# DDR16SS0_CTLPHY_WRAP_CTL_CFG_CTLCFG register map
Vendor: Texas Instruments
Registers are 32-bit, read-write, reset 0x0 unless marked. A register's access mark holds for its fields unless they carry their own. Offsets are as the file gives them; [hi:lo] are bit positions; {n}, {i} and the like mark numbered series.

## DDR16SS0_CTLPHY_WRAP_CTL_CFG_CTLCFG (part 8 of 9)
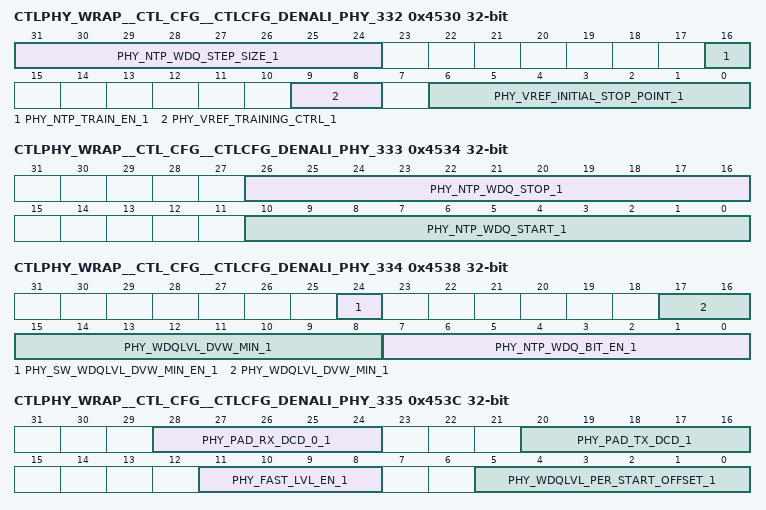
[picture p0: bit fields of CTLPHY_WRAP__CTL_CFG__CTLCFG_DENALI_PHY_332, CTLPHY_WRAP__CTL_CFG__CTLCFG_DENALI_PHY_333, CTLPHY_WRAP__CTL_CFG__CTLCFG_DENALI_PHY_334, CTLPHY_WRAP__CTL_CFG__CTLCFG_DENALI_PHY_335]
0x4530 CTLPHY_WRAP__CTL_CFG__CTLCFG_DENALI_PHY_332
  [31:24] PHY_NTP_WDQ_STEP_SIZE_1 — Step size of WR DQ slave delay during No-Topology training for slice 1.
  [16] PHY_NTP_TRAIN_EN_1 — Enable for No-Topology training for slice 1.
  [9:8] PHY_VREF_TRAINING_CTRL_1 — Data slice vref training enable control for slice 1.
  [6:0] PHY_VREF_INITIAL_STOP_POINT_1 — Data slice initial VREF training stop value for slice 1.
0x4534 CTLPHY_WRAP__CTL_CFG__CTLCFG_DENALI_PHY_333
  [26:16] PHY_NTP_WDQ_STOP_1 — End of WR DQ slave delay in No-Topology training for slice 1.
  [10:0] PHY_NTP_WDQ_START_1 — Starting WR DQ slave delay in No-Topology training for slice 1.
0x4538 CTLPHY_WRAP__CTL_CFG__CTLCFG_DENALI_PHY_334
  [24] PHY_SW_WDQLVL_DVW_MIN_EN_1 — SW override to enable use of PHY_WDQLVL_DVW_MIN for slice 1.
  [17:8] PHY_WDQLVL_DVW_MIN_1 — Minimum data valid window across DQs and ranks for slice 1.
  [7:0] PHY_NTP_WDQ_BIT_EN_1 — Enable Bit for WR DQ during No-Topology training for slice 1.
0x453C CTLPHY_WRAP__CTL_CFG__CTLCFG_DENALI_PHY_335
  [28:24] PHY_PAD_RX_DCD_0_1 — Controls RX_DCD pin for each pad for slice 1.
  [20:16] PHY_PAD_TX_DCD_1 — Controls TX_DCD pin for each pad for slice 1.
  [11:8] PHY_FAST_LVL_EN_1 — Enable for fast multi-pattern window search for slice 1.
  [5:0] PHY_WDQLVL_PER_START_OFFSET_1 — Peridic training start point offset for slice 1.
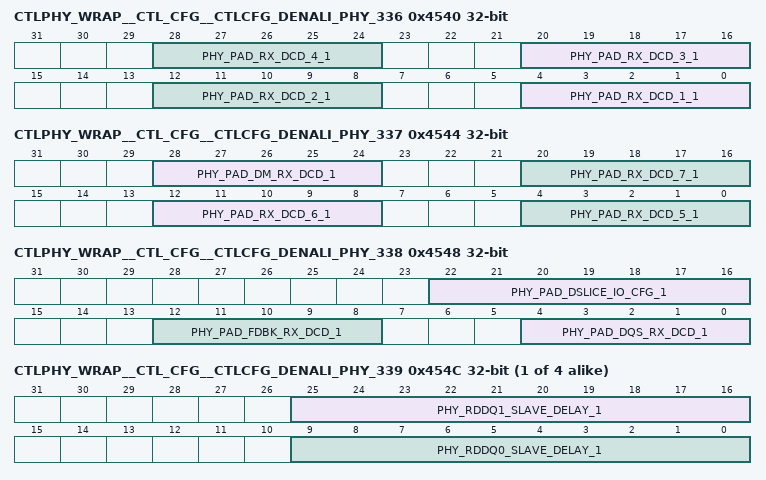
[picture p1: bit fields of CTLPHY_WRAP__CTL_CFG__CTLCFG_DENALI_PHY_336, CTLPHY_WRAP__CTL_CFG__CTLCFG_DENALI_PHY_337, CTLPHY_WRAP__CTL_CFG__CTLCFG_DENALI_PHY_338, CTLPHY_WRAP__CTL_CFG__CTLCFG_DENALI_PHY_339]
0x4540 CTLPHY_WRAP__CTL_CFG__CTLCFG_DENALI_PHY_336
  [8n-4:8n-8] PHY_PAD_RX_DCD_{n}_1 (n=1..4) — Controls RX_DCD pin for each pad for slice 1.
0x4544 CTLPHY_WRAP__CTL_CFG__CTLCFG_DENALI_PHY_337
  [28:24] PHY_PAD_DM_RX_DCD_1 — Controls RX_DCD pin for dm pad for slice 1.
  [20:16] PHY_PAD_RX_DCD_7_1 — Controls RX_DCD pin for each pad for slice 1.
  [12:8] PHY_PAD_RX_DCD_6_1 — Controls RX_DCD pin for each pad for slice 1.
  [4:0] PHY_PAD_RX_DCD_5_1 — Controls RX_DCD pin for each pad for slice 1.
0x4548 CTLPHY_WRAP__CTL_CFG__CTLCFG_DENALI_PHY_338
  [22:16] PHY_PAD_DSLICE_IO_CFG_1 — Controls PCLK/PARK pin for pad for slice 1.
  [12:8] PHY_PAD_FDBK_RX_DCD_1 — Controls RX_DCD pin for fdbk pad for slice 1.
  [4:0] PHY_PAD_DQS_RX_DCD_1 — Controls RX_DCD pin for dqs pad for slice 1.
{0x4000+4i} CTLPHY_WRAP__CTL_CFG__CTLCFG_DENALI_PHY_{i} (i=339..342)
  [25:16] PHY_RDDQ{2i-677}_SLAVE_DELAY_1 — Read DQ{2i-677} slave delay setting for slice 1.
  [9:0] PHY_RDDQ{2i-678}_SLAVE_DELAY_1 — Read DQ{2i-678} slave delay setting for slice 1.
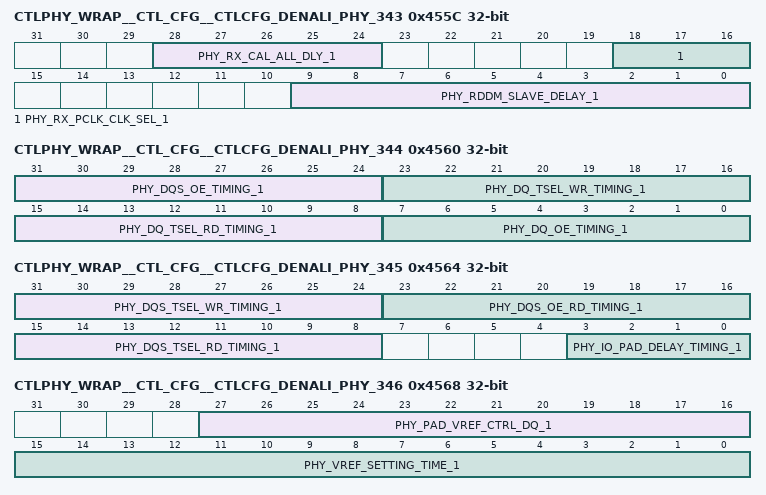
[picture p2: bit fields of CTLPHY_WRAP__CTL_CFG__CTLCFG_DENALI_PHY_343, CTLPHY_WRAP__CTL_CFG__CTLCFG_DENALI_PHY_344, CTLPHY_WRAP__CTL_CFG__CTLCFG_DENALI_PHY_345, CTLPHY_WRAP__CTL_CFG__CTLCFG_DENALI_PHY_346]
0x455C CTLPHY_WRAP__CTL_CFG__CTLCFG_DENALI_PHY_343
  [28:24] PHY_RX_CAL_ALL_DLY_1 — Defines the number of cycles/half cycles that the rx_cal_all_opad signal should be asserted for. There is a phy_rx_cal_all_dly_X parameter for each of the slices of data sent on the DFI data bus for slice 1.
  [18:16] PHY_RX_PCLK_CLK_SEL_1 — RX_PCLK clock frequency selection for slice 1.
  [9:0] PHY_RDDM_SLAVE_DELAY_1 — Read DM/DBI slave delay setting for slice 1. May be used for data swap.
0x4560 CTLPHY_WRAP__CTL_CFG__CTLCFG_DENALI_PHY_344
  [31:24] PHY_DQS_OE_TIMING_1 — Start/end timing values for DQS output enable signals for slice 1.
  [23:16] PHY_DQ_TSEL_WR_TIMING_1 — Start/end timing values for DQ/DM write based termination enable and select signals for slice 1.
  [15:8] PHY_DQ_TSEL_RD_TIMING_1 — Start/end timing values for DQ/DM read based termination enable and select signals for slice 1.
  [7:0] PHY_DQ_OE_TIMING_1 — Start/end timing values for DQ/DM output enable signals for slice 1.
0x4564 CTLPHY_WRAP__CTL_CFG__CTLCFG_DENALI_PHY_345
  [31:24] PHY_DQS_TSEL_WR_TIMING_1 — Start/end timing values for DQS write based termination enable and select signals for slice 1.
  [23:16] PHY_DQS_OE_RD_TIMING_1 — Start/end timing values for DQS read based OE extension for slice 1.
  [15:8] PHY_DQS_TSEL_RD_TIMING_1 — Start/end timing values for DQS read based termination enable and select signals for slice 1.
  [3:0] PHY_IO_PAD_DELAY_TIMING_1 — Feedback pad's OPAD and IPAD delay timing for slice 1.
0x4568 CTLPHY_WRAP__CTL_CFG__CTLCFG_DENALI_PHY_346
  [27:16] PHY_PAD_VREF_CTRL_DQ_1 — Pad VREF control settings for DQ slice 1.
  [15:0] PHY_VREF_SETTING_TIME_1 — Number of cycles for vref settle after setting is changed for slice 1.
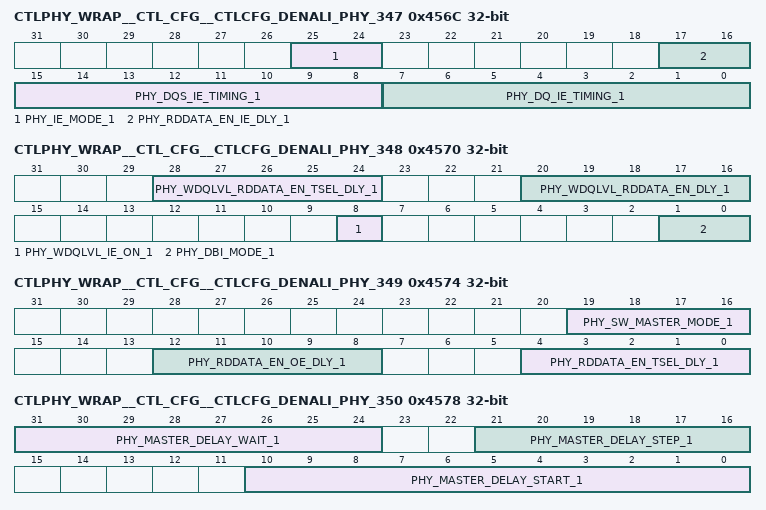
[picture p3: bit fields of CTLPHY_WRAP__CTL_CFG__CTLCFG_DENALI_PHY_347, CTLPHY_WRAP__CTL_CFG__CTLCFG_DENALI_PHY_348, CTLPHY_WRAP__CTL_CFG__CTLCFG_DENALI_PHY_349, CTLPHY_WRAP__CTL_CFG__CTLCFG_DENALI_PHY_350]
0x456C CTLPHY_WRAP__CTL_CFG__CTLCFG_DENALI_PHY_347
  [25:24] PHY_IE_MODE_1 — Input enable mode bits for slice 1. Bit [0] enables the mode where the input enables are always on; set to 1 to enable. Bit [1] disables the input enable on the DM signal; set to 1 to disable.
  [17:16] PHY_RDDATA_EN_IE_DLY_1 — Number of cycles that the dfi_rddata_en signal is earlier than necessary for input enable generation for slice 1.
  [15:8] PHY_DQS_IE_TIMING_1 — Start/end timing values for DQS input enable signals for slice 1.
  [7:0] PHY_DQ_IE_TIMING_1 — Start/end timing values for DQ/DM input enable signals for slice 1.
0x4570 CTLPHY_WRAP__CTL_CFG__CTLCFG_DENALI_PHY_348
  [28:24] PHY_WDQLVL_RDDATA_EN_TSEL_DLY_1 — For WR DQ training, the number of cycles that the dfi_rddata_en signal is earlier than necessary for TSEL enable generation for slice 1.
  [20:16] PHY_WDQLVL_RDDATA_EN_DLY_1 — For WR DQ training, the number of cycles that the dfi_rddata_en signal is early for slice 1.
  [8] PHY_WDQLVL_IE_ON_1 — IE control, 1 meams IE is always on during WR DQ training for slice 1.
  [1:0] PHY_DBI_MODE_1 — DBI mode for slice 1. Bit [0] enables return of DBI read data.
0x4574 CTLPHY_WRAP__CTL_CFG__CTLCFG_DENALI_PHY_349
  [19:16] PHY_SW_MASTER_MODE_1 — Master delay line override settings for slice 1. Bit [0] enables software half clock mode. Bit [1] is the software half clock mode value. Bit [2] enables software bypass mode. Bit [3] is the software bypass mode value.
  [12:8] PHY_RDDATA_EN_OE_DLY_1 — Number of cycles that the dfi_rddata_en signal is earlier than necessary for LP4 OE extension generation for slice 1.
  [4:0] PHY_RDDATA_EN_TSEL_DLY_1 — Number of cycles that the dfi_rddata_en signal is earlier than necessary for TSEL enable generation for slice 1.
0x4578 CTLPHY_WRAP__CTL_CFG__CTLCFG_DENALI_PHY_350
  [31:24] PHY_MASTER_DELAY_WAIT_1 — Wait cycles for master delay line locking algorithm for slice 1. Bits [3:0] are the cycle wait count after a calibration clock setting change. Bits [7:4] are the cycle wait count after a master delay setting change.
  [21:16] PHY_MASTER_DELAY_STEP_1 — Incremental step size for master delay line locking algorithm for slice 1.
  [10:0] PHY_MASTER_DELAY_START_1 — Start value for master delay line locking algorithm for slice 1.
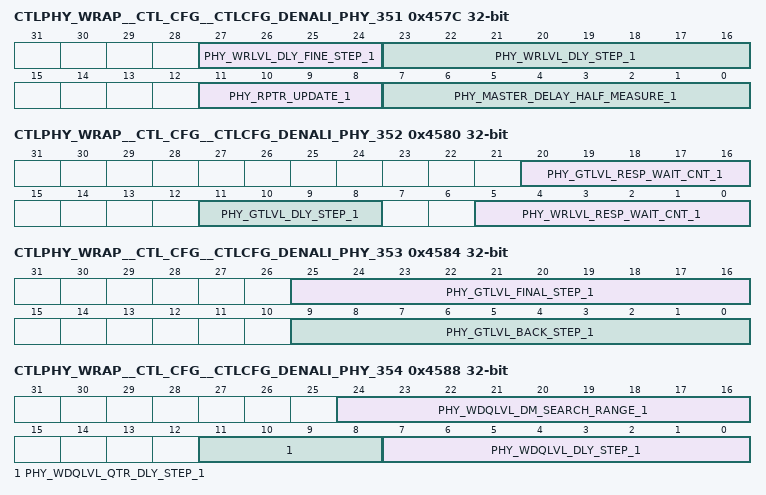
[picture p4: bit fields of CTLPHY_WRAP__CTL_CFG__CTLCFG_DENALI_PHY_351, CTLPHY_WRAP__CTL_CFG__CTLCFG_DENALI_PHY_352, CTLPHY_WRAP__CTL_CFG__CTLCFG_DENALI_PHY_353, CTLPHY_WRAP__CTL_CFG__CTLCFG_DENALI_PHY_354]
0x457C CTLPHY_WRAP__CTL_CFG__CTLCFG_DENALI_PHY_351
  [27:24] PHY_WRLVL_DLY_FINE_STEP_1 — DQS slave delay fine step size during write leveling for slice 1.
  [23:16] PHY_WRLVL_DLY_STEP_1 — DQS slave delay step size during write leveling for slice 1.
  [11:8] PHY_RPTR_UPDATE_1 — Offset in cycles from the dfi_rddata_en signal to release data from the entry FIFO for slice 1.
  [7:0] PHY_MASTER_DELAY_HALF_MEASURE_1 — Defines the number of delay line elements to be considered in determing whether to lock to a half clock cycle in the data slice master for slice 1.
0x4580 CTLPHY_WRAP__CTL_CFG__CTLCFG_DENALI_PHY_352
  [20:16] PHY_GTLVL_RESP_WAIT_CNT_1 — Number of cycles + 4 to wait between dfi_rddata_en and the sampling of the DQS during gate training for slice 1. The valid range is 0x0 to 0xB.
  [11:8] PHY_GTLVL_DLY_STEP_1 — DQS slave delay step size during gate training for slice 1.
  [5:0] PHY_WRLVL_RESP_WAIT_CNT_1 — Number of cycles to wait between dfi_wrlvl_strobe and the sampling of the DQs during write leveling for slice 1.
0x4584 CTLPHY_WRAP__CTL_CFG__CTLCFG_DENALI_PHY_353
  [25:16] PHY_GTLVL_FINAL_STEP_1 — Final backup step delay used in gate training algorithm for slice 1.
  [9:0] PHY_GTLVL_BACK_STEP_1 — Interim backup step delay used in gate training algorithm for slice 1.
0x4588 CTLPHY_WRAP__CTL_CFG__CTLCFG_DENALI_PHY_354
  [24:16] PHY_WDQLVL_DM_SEARCH_RANGE_1 — The dm slave delay search range for non-lpddr4 DM training for slice 1.
  [11:8] PHY_WDQLVL_QTR_DLY_STEP_1 — Defines the step granularity for the logic to use once an edge is found for slice 1. When this occurs, the logic jumps back to the previous invalid value and uses this step size to determine a more accurate delay value.
  [7:0] PHY_WDQLVL_DLY_STEP_1 — DQ slave delay step size during write data leveling for slice 1.
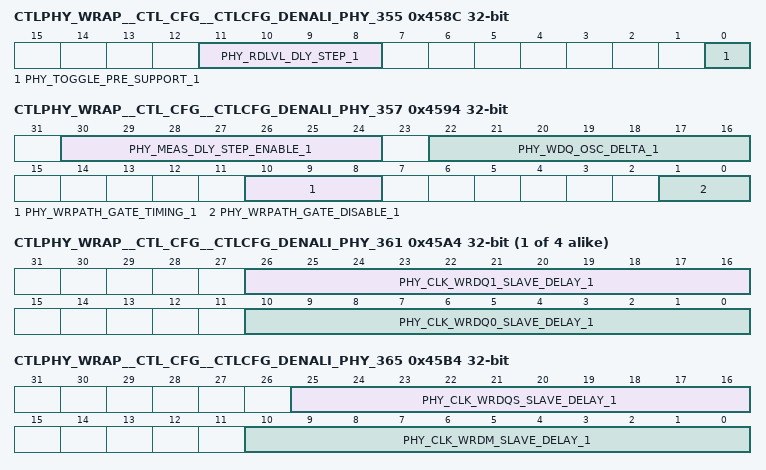
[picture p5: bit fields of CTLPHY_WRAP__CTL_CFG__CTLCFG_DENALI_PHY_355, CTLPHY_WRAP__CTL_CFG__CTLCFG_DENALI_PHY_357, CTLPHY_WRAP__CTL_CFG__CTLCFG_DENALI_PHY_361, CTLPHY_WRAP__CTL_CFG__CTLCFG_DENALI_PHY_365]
0x458C CTLPHY_WRAP__CTL_CFG__CTLCFG_DENALI_PHY_355
  [11:8] PHY_RDLVL_DLY_STEP_1 — DQS slave delay step size during read leveling for slice 1.
  [0] PHY_TOGGLE_PRE_SUPPORT_1 — Support the toggle read preamble for LPDDR4 for slice 1.
0x4590 CTLPHY_WRAP__CTL_CFG__CTLCFG_DENALI_PHY_356
  [9:0] PHY_RDLVL_MAX_EDGE_1 — The maximun rdlvl slave delay search window for read eye training for slice 1.
0x4594 CTLPHY_WRAP__CTL_CFG__CTLCFG_DENALI_PHY_357
  [30:24] PHY_MEAS_DLY_STEP_ENABLE_1 — Data slice training step definition using phy_meas_dly_step_value for slice 1.
  [22:16] PHY_WDQ_OSC_DELTA_1 — Slave delay offset that applies to a 1 bit change of dfi_wdq_osc_code for slice 1.
  [10:8] PHY_WRPATH_GATE_TIMING_1 — Write path clock gating timing for slice 1. it means additional clock number to write path clock gate
  [1:0] PHY_WRPATH_GATE_DISABLE_1 — Write path clock gating disable for slice 1. [0]: disable pull in wrdata_en; [1]: disable write path clock gating, clock always on
0x4598 CTLPHY_WRAP__CTL_CFG__CTLCFG_DENALI_PHY_358
  [4:0] PHY_RDDATA_EN_DLY_1 — Number of cycles that the dfi_rddata_en signal is early for slice 1.
0x459C CTLPHY_WRAP__CTL_CFG__CTLCFG_DENALI_PHY_359
  [31:0] PHY_DQ_DM_SWIZZLE0_1 — DQ/DM bit swizzling 0 for slice 1. Bits [3:0] inform the PHY which bit in {DM,DQ]} map to DQ0, Bits [7:4] inform the PHY which bit in {DM,DQ} map to DQ1, etc.
0x45A0 CTLPHY_WRAP__CTL_CFG__CTLCFG_DENALI_PHY_360
  [3:0] PHY_DQ_DM_SWIZZLE1_1 — DQ/DM bit swizzling 1 for slice 1. Bits [3:0] inform the PHY which bit in {DM,DQ]} map to DM.
{0x4000+4i} CTLPHY_WRAP__CTL_CFG__CTLCFG_DENALI_PHY_{i} (i=361..364)
  [26:16] PHY_CLK_WRDQ{2i-721}_SLAVE_DELAY_1 — Write clock slave delay setting for DQ{2i-721} for slice 1.
  [10:0] PHY_CLK_WRDQ{2i-722}_SLAVE_DELAY_1 — Write clock slave delay setting for DQ{2i-722} for slice 1.
0x45B4 CTLPHY_WRAP__CTL_CFG__CTLCFG_DENALI_PHY_365
  [25:16] PHY_CLK_WRDQS_SLAVE_DELAY_1 — Write clock slave delay setting for DQS for slice 1.
  [10:0] PHY_CLK_WRDM_SLAVE_DELAY_1 — Write clock slave delay setting for DM for slice 1.
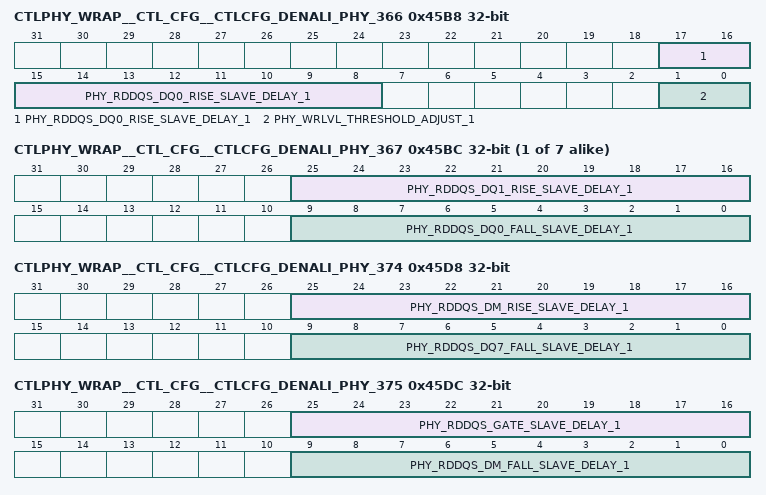
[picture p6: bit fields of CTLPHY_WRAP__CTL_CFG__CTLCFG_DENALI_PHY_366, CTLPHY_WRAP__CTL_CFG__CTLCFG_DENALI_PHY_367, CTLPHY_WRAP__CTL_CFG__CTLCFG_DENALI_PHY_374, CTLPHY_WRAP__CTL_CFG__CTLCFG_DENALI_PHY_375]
0x45B8 CTLPHY_WRAP__CTL_CFG__CTLCFG_DENALI_PHY_366
  [17:8] PHY_RDDQS_DQ0_RISE_SLAVE_DELAY_1 — Rising edge read DQS slave delay setting for DQ0 for slice 1.
  [1:0] PHY_WRLVL_THRESHOLD_ADJUST_1 — Write level threshold adjust value based on those thresholds for DQS for slice 1.
{0x4000+4i} CTLPHY_WRAP__CTL_CFG__CTLCFG_DENALI_PHY_{i} (i=367..373)
  [25:16] PHY_RDDQS_DQ{i-366}_RISE_SLAVE_DELAY_1 — Rising edge read DQS slave delay setting for DQ{i-366} for slice 1.
  [9:0] PHY_RDDQS_DQ{i-367}_FALL_SLAVE_DELAY_1 — Falling edge read DQS slave delay setting for DQ{i-367} for slice 1.
0x45D8 CTLPHY_WRAP__CTL_CFG__CTLCFG_DENALI_PHY_374
  [25:16] PHY_RDDQS_DM_RISE_SLAVE_DELAY_1 — Rising edge read DQS slave delay setting for DM for slice 1.
  [9:0] PHY_RDDQS_DQ7_FALL_SLAVE_DELAY_1 — Falling edge read DQS slave delay setting for DQ7 for slice 1.
0x45DC CTLPHY_WRAP__CTL_CFG__CTLCFG_DENALI_PHY_375
  [25:16] PHY_RDDQS_GATE_SLAVE_DELAY_1 — Read DQS slave delay setting for slice 1.
  [9:0] PHY_RDDQS_DM_FALL_SLAVE_DELAY_1 — Falling edge read DQS slave delay setting for DM for slice 1.
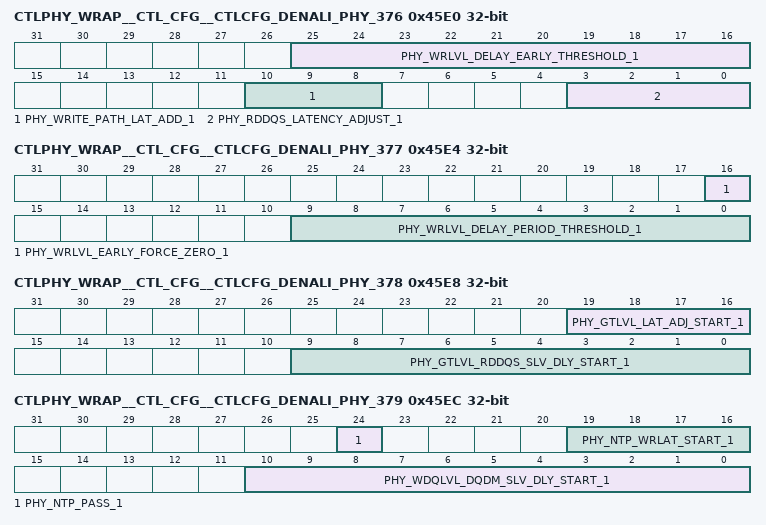
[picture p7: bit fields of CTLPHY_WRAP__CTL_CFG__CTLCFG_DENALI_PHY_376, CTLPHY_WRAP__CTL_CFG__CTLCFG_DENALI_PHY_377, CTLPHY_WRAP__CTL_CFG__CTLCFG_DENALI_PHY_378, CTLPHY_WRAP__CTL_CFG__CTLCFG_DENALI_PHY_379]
0x45E0 CTLPHY_WRAP__CTL_CFG__CTLCFG_DENALI_PHY_376
  [25:16] PHY_WRLVL_DELAY_EARLY_THRESHOLD_1 — Write level delay threshold above which will be considered in previous cycle for slice 1.
  [10:8] PHY_WRITE_PATH_LAT_ADD_1 — Number of cycles to delay the incoming dfi_wrdata_en/dfi_wrdata signals for slice 1.
  [3:0] PHY_RDDQS_LATENCY_ADJUST_1 — Number of cycles to delay the incoming dfi_rddata_en for read DQS gate generation for slice 1.
0x45E4 CTLPHY_WRAP__CTL_CFG__CTLCFG_DENALI_PHY_377
  [16] PHY_WRLVL_EARLY_FORCE_ZERO_1 — Force the final write level delay value [that meets the early threshold] to 0 for slice 1.
  [9:0] PHY_WRLVL_DELAY_PERIOD_THRESHOLD_1 — Write level delay threshold below which will add a cycle of write path latency for slice 1.
0x45E8 CTLPHY_WRAP__CTL_CFG__CTLCFG_DENALI_PHY_378
  [19:16] PHY_GTLVL_LAT_ADJ_START_1 — Initial read DQS gate cycle delay from dfi_rddata_en during gate training for slice 1.
  [9:0] PHY_GTLVL_RDDQS_SLV_DLY_START_1 — Initial read DQS gate slave delay setting during gate training for slice 1.
0x45EC CTLPHY_WRAP__CTL_CFG__CTLCFG_DENALI_PHY_379
  [24] PHY_NTP_PASS_1 — Indicates if No-topology training found a passing result for slice 1.
  [19:16] PHY_NTP_WRLAT_START_1 — Initial value for phy_write_path_lat_add for No-topology training and early threshold for slice 1.
  [10:0] PHY_WDQLVL_DQDM_SLV_DLY_START_1 — Initial DQ/DM slave delay setting during write data leveling for slice 1.
0x45F0 CTLPHY_WRAP__CTL_CFG__CTLCFG_DENALI_PHY_380
  [9:0] PHY_RDLVL_RDDQS_DQ_SLV_DLY_START_1 — Read leveling starting value for the DQS/DQ slave delay settings for slice 1.
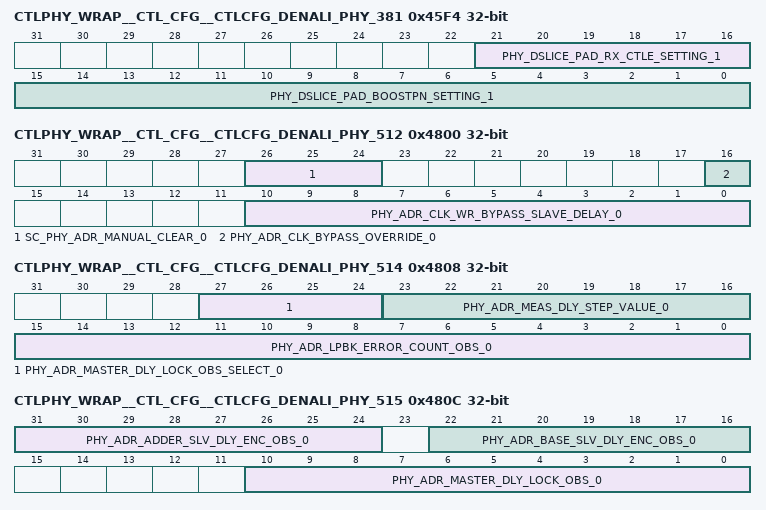
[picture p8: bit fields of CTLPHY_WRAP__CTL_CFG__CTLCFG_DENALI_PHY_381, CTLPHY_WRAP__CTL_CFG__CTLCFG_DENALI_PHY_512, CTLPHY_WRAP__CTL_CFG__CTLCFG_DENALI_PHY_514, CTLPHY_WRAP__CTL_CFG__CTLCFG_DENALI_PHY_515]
0x45F4 CTLPHY_WRAP__CTL_CFG__CTLCFG_DENALI_PHY_381
  [21:16] PHY_DSLICE_PAD_RX_CTLE_SETTING_1 — Setting for RX ctle P/N of pad for slice 1.
  [15:0] PHY_DSLICE_PAD_BOOSTPN_SETTING_1 — Setting for boost P/N of pad for slice 1.
0x4800 CTLPHY_WRAP__CTL_CFG__CTLCFG_DENALI_PHY_512 access per field
  [26:24] SC_PHY_ADR_MANUAL_CLEAR_0 wo — Manual reset/clear of internal logic for address slice 0. Bit [0] is reset of master delay min/max lock values. Bit [1] is manual reset of master delay unlock counter. Bit [2] clears the loopback error/results registers. Set each bit to 1 to reset. WRITE-ONLY
  [16] PHY_ADR_CLK_BYPASS_OVERRIDE_0 rw — Bypass mode override setting for address slice 0. Set to 1 to enable.
  [10:0] PHY_ADR_CLK_WR_BYPASS_SLAVE_DELAY_0 rw — Command/Address clock bypass mode slave delay setting for address slice 0.
0x4804 CTLPHY_WRAP__CTL_CFG__CTLCFG_DENALI_PHY_513 ro reset 0x1000
  [31:0] PHY_ADR_LPBK_RESULT_OBS_0 — Observation register containing loopback status/results for address slice 0. READ-ONLY
0x4808 CTLPHY_WRAP__CTL_CFG__CTLCFG_DENALI_PHY_514 access per field
  [27:24] PHY_ADR_MASTER_DLY_LOCK_OBS_SELECT_0 rw — Select value to map the internal master delay observation registers to the accessible master delay observation register for address slice 0.
  [23:16] PHY_ADR_MEAS_DLY_STEP_VALUE_0 ro — Contains the fraction of a cycle in 1 delay element numerator with demominator of 512, for address slice 0. READ-ONLY
  [15:0] PHY_ADR_LPBK_ERROR_COUNT_OBS_0 ro — Observation register containing total number of loopback error data for address slice 0. READ-ONLY
0x480C CTLPHY_WRAP__CTL_CFG__CTLCFG_DENALI_PHY_515 ro
  [31:24] PHY_ADR_ADDER_SLV_DLY_ENC_OBS_0 — Observation register containing addr slave delay for address slice 0. READ-ONLY
  [22:16] PHY_ADR_BASE_SLV_DLY_ENC_OBS_0 — Observation register containing base slave delay for address slice 0. READ-ONLY
  [10:0] PHY_ADR_MASTER_DLY_LOCK_OBS_0 — Observation register containing master delay results for address slice 0. READ-ONLY
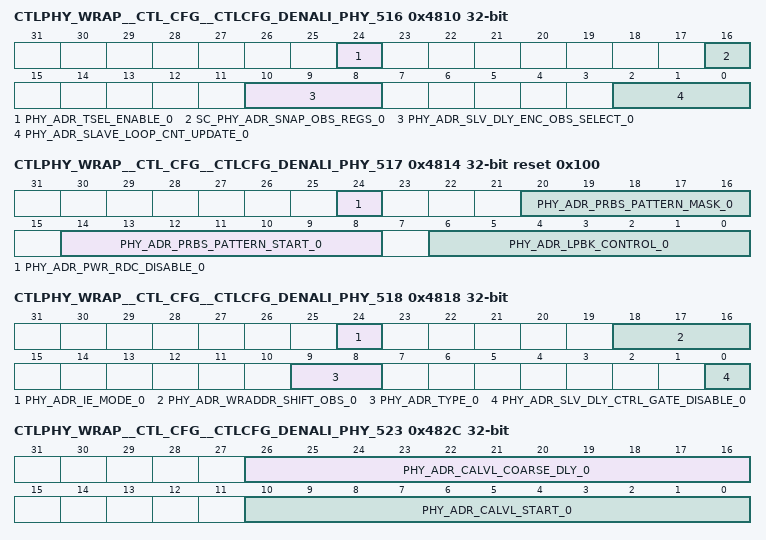
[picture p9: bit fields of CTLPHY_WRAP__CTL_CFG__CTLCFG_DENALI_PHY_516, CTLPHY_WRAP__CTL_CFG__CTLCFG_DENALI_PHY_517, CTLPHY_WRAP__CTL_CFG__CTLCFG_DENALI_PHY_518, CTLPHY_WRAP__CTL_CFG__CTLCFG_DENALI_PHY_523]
0x4810 CTLPHY_WRAP__CTL_CFG__CTLCFG_DENALI_PHY_516 access per field
  [24] PHY_ADR_TSEL_ENABLE_0 rw — Enables tsel_en for address slice 0.
  [16] SC_PHY_ADR_SNAP_OBS_REGS_0 wo — Initiates a snapshot of the internal observation registers for address slice 0. Set to 1 to trigger. WRITE-ONLY
  [10:8] PHY_ADR_SLV_DLY_ENC_OBS_SELECT_0 rw — Select value to map the addr bits delay observation registers to the accessible delay observation register for address slice 0.
  [2:0] PHY_ADR_SLAVE_LOOP_CNT_UPDATE_0 rw — Reserved for address slice 0.
0x4814 CTLPHY_WRAP__CTL_CFG__CTLCFG_DENALI_PHY_517 reset 0x100
  [24] PHY_ADR_PWR_RDC_DISABLE_0 — Power reduction disable for address slice 0.
  [20:16] PHY_ADR_PRBS_PATTERN_MASK_0 — PRBS7 mask signal for address slice 0.
  [14:8] PHY_ADR_PRBS_PATTERN_START_0 — PRBS7 start pattern for address slice 0.
  [6:0] PHY_ADR_LPBK_CONTROL_0 — Loopback control bits for address slice 0.
0x4818 CTLPHY_WRAP__CTL_CFG__CTLCFG_DENALI_PHY_518 access per field
  [24] PHY_ADR_IE_MODE_0 rw — Input enable control for address slice 0.
  [18:16] PHY_ADR_WRADDR_SHIFT_OBS_0 ro — Observation register containing automatic half cycle and cycle shift values for address slice 0. READ-ONLY
  [9:8] PHY_ADR_TYPE_0 rw — DRAM type for address slice 0.
  [0] PHY_ADR_SLV_DLY_CTRL_GATE_DISABLE_0 rw — Power reduction slv_dly_control block gate disable for address slice 0.
0x481C CTLPHY_WRAP__CTL_CFG__CTLCFG_DENALI_PHY_519
  [26:0] PHY_ADR_DDL_MODE_0 — DDL mode for address slice 0.
0x4820 CTLPHY_WRAP__CTL_CFG__CTLCFG_DENALI_PHY_520
  [5:0] PHY_ADR_DDL_MASK_0 — DDL mask for address slice 0.
0x4824 CTLPHY_WRAP__CTL_CFG__CTLCFG_DENALI_PHY_521 ro
  [31:0] PHY_ADR_DDL_TEST_OBS_0 — Observation register containing DDL test bits for address slice 0. READ-ONLY
0x4828 CTLPHY_WRAP__CTL_CFG__CTLCFG_DENALI_PHY_522 ro
  [31:0] PHY_ADR_DDL_TEST_MSTR_DLY_OBS_0 — Observation register containing master DDL bits for address slice 0. READ-ONLY
0x482C CTLPHY_WRAP__CTL_CFG__CTLCFG_DENALI_PHY_523
  [26:16] PHY_ADR_CALVL_COARSE_DLY_0 — Coarse CA training DDL increment value for address slice 0.
  [10:0] PHY_ADR_CALVL_START_0 — CA training DDL start value for address slice 0.
0x4830 CTLPHY_WRAP__CTL_CFG__CTLCFG_DENALI_PHY_524
  [10:0] PHY_ADR_CALVL_QTR_0 — CA training DDL quarter cycle delay value for address slice 0.
0x4834 CTLPHY_WRAP__CTL_CFG__CTLCFG_DENALI_PHY_525
  [23:0] PHY_ADR_CALVL_SWIZZLE0_0 — CA training RD DQ bit swizzle map 0 for address slice 0.
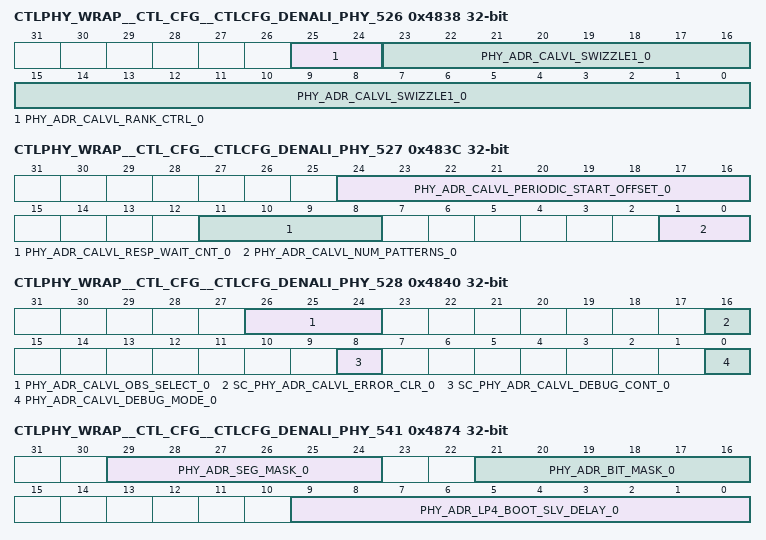
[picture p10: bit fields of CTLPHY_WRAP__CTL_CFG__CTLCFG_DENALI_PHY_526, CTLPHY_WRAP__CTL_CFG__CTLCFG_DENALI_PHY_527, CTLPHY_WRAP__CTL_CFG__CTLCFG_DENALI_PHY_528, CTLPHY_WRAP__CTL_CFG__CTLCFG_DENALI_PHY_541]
0x4838 CTLPHY_WRAP__CTL_CFG__CTLCFG_DENALI_PHY_526
  [25:24] PHY_ADR_CALVL_RANK_CTRL_0 — CA training rank aggregation control bits for address slice 0.
  [23:0] PHY_ADR_CALVL_SWIZZLE1_0 — CA training RD DQ bit swizzle map 1 for address slice 0.
0x483C CTLPHY_WRAP__CTL_CFG__CTLCFG_DENALI_PHY_527
  [24:16] PHY_ADR_CALVL_PERIODIC_START_OFFSET_0 — Relative offset to start periodic CALVL from previous result
  [11:8] PHY_ADR_CALVL_RESP_WAIT_CNT_0 — Number of samples to wait before sampling response during CA training for address slice 0.
  [1:0] PHY_ADR_CALVL_NUM_PATTERNS_0 — Number of patterns to use during CA training for address slice 0.
0x4840 CTLPHY_WRAP__CTL_CFG__CTLCFG_DENALI_PHY_528 access per field
  [26:24] PHY_ADR_CALVL_OBS_SELECT_0 rw — CA bit lane to observe result from OBS0 during CA training for address slice 0.
  [16] SC_PHY_ADR_CALVL_ERROR_CLR_0 wo — Clears the CA training state machine error status for address slice 0. Set to 1 to trigger. WRITE-ONLY
  [8] SC_PHY_ADR_CALVL_DEBUG_CONT_0 wo — Allows the CA training state machine to advance [when in debug mode] for address slice 0. Set to 1 to trigger. WRITE-ONLY
  [0] PHY_ADR_CALVL_DEBUG_MODE_0 rw — Enables CA training debug mode for address slice 0. Set to 1 to enable.
0x4844 CTLPHY_WRAP__CTL_CFG__CTLCFG_DENALI_PHY_529 ro
  [31:0] PHY_ADR_CALVL_OBS0_0 — Observation register contains lane specific CA training bits for slice 0. READ-ONLY
0x4848 CTLPHY_WRAP__CTL_CFG__CTLCFG_DENALI_PHY_530 ro
  [31:0] PHY_ADR_CALVL_OBS1_0 — Observation register contains general CA training bits for slice 0. READ-ONLY
0x484C CTLPHY_WRAP__CTL_CFG__CTLCFG_DENALI_PHY_531 ro reset 0x100
  [31:0] PHY_ADR_CALVL_OBS2_0 — Observation register contains periodic CA training bits for slice 0. READ-ONLY
0x4850 CTLPHY_WRAP__CTL_CFG__CTLCFG_DENALI_PHY_532
  [19:0] PHY_ADR_CALVL_FG_0_0 — CA training foreground pattern 0 for address slice 0.
0x4854 CTLPHY_WRAP__CTL_CFG__CTLCFG_DENALI_PHY_533
  [19:0] PHY_ADR_CALVL_BG_0_0 — CA training background pattern 0 for address slice 0.
0x4858 CTLPHY_WRAP__CTL_CFG__CTLCFG_DENALI_PHY_534
  [19:0] PHY_ADR_CALVL_FG_1_0 — CA training foreground pattern 1 for address slice 0.
0x485C CTLPHY_WRAP__CTL_CFG__CTLCFG_DENALI_PHY_535
  [19:0] PHY_ADR_CALVL_BG_1_0 — CA training background pattern 1 for address slice 0.
0x4860 CTLPHY_WRAP__CTL_CFG__CTLCFG_DENALI_PHY_536
  [19:0] PHY_ADR_CALVL_FG_2_0 — CA training foreground pattern 2 for address slice 0.
0x4864 CTLPHY_WRAP__CTL_CFG__CTLCFG_DENALI_PHY_537
  [19:0] PHY_ADR_CALVL_BG_2_0 — CA training background pattern 2 for address slice 0.
0x4868 CTLPHY_WRAP__CTL_CFG__CTLCFG_DENALI_PHY_538
  [19:0] PHY_ADR_CALVL_FG_3_0 — CA training foreground pattern 3 for address slice 0.
0x486C CTLPHY_WRAP__CTL_CFG__CTLCFG_DENALI_PHY_539
  [19:0] PHY_ADR_CALVL_BG_3_0 — CA training background pattern 3 for address slice 0.
0x4870 CTLPHY_WRAP__CTL_CFG__CTLCFG_DENALI_PHY_540
  [29:0] PHY_ADR_ADDR_SEL_0 — Selects which DFI address pins connect to which CA pins for LPDDR3/4 for address slice 0.
0x4874 CTLPHY_WRAP__CTL_CFG__CTLCFG_DENALI_PHY_541
  [29:24] PHY_ADR_SEG_MASK_0 — Segment mask bit for address slice 0. Set to 1 to indicate that the bit is either CA 4 or CA 9.
  [21:16] PHY_ADR_BIT_MASK_0 — Mask bit for address slice 0. Set to 1 to indicate that the bit is used.
  [9:0] PHY_ADR_LP4_BOOT_SLV_DELAY_0 — Address slave delay setting during the LPDDR4 boot frequency operation for address slice 0.
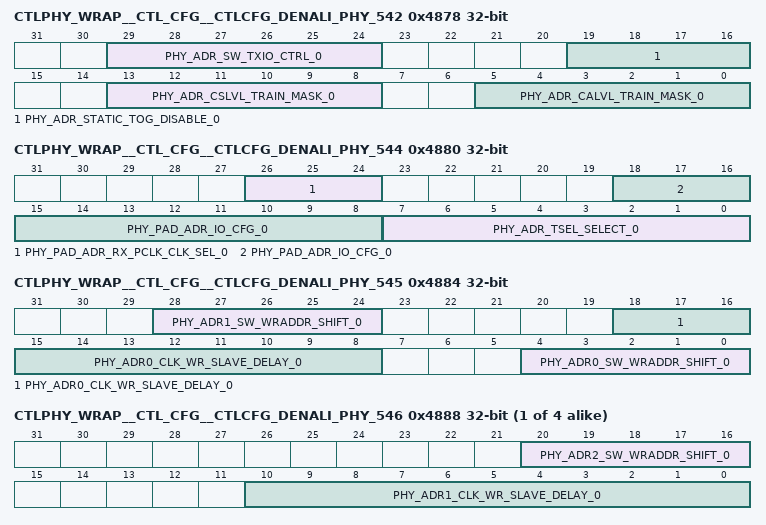
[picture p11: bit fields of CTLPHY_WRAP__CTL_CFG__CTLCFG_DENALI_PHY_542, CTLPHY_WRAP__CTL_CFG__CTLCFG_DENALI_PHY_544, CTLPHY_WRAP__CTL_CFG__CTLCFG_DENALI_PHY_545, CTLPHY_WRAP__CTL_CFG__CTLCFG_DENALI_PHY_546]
0x4878 CTLPHY_WRAP__CTL_CFG__CTLCFG_DENALI_PHY_542
  [29:24] PHY_ADR_SW_TXIO_CTRL_0 — Controls address pad output enable for address slice 0. Set to 1 to disable output enable.
  [19:16] PHY_ADR_STATIC_TOG_DISABLE_0 — Toggle control during static activity for address slice 0. Set bit to dsiable toggling, bit0: Write path delay line, bit1: Read path delay line, bit2: Read data path, bit3: clk_phy, bit4: master delay line.
  [13:8] PHY_ADR_CSLVL_TRAIN_MASK_0 — Mask bit for CS training participation for address slice 0. Set to 1 to indicate that the bit is participating in CS training.
  [5:0] PHY_ADR_CALVL_TRAIN_MASK_0 — Mask bit for CA training participation for address slice 0. Set to 1 to indicate that the bit is participating in CA training.
0x487C CTLPHY_WRAP__CTL_CFG__CTLCFG_DENALI_PHY_543
  [5:0] PHY_ADR_SW_TXPWR_CTRL_0 — Disable address output enables in deep sleep mode for address slice 0.
0x4880 CTLPHY_WRAP__CTL_CFG__CTLCFG_DENALI_PHY_544
  [26:24] PHY_PAD_ADR_RX_PCLK_CLK_SEL_0 — Reserved for address slice 0.
  [18:8] PHY_PAD_ADR_IO_CFG_0 — Controls I/O pads for address pad for address slice 0. Bits [10:5] = Park value, bits [4] park override, bits [2:0] clk divider.
  [7:0] PHY_ADR_TSEL_SELECT_0 — Tsel select values for address slice 0.
0x4884 CTLPHY_WRAP__CTL_CFG__CTLCFG_DENALI_PHY_545
  [28:24] PHY_ADR1_SW_WRADDR_SHIFT_0 — Manual override of CA bit 1 of automatic half_cycle_shift/cycle_shift for address slice 0. Bit [0] enables override of half_cycle_shift. Bit [1] is the half_cycle_shift value. Bit [2] enables override of cycle shift. Bits [4:3] is the cycle_shift value. For bits [4:3], clear to 0x0 for no offset, program to 0x1 for -1 cycle, program to 0x2 for +1 cycle, or program to 0x3 for -2 cycles.
  [18:8] PHY_ADR0_CLK_WR_SLAVE_DELAY_0 — CA bit 0 slave delay setting for address slice 0.
  [4:0] PHY_ADR0_SW_WRADDR_SHIFT_0 — Manual override of CA bit 0 of automatic half_cycle_shift/cycle_shift for address slice 0. Bit [0] enables override of half_cycle_shift. Bit [1] is the half_cycle_shift value. Bit [2] enables override of cycle shift. Bits [4:3] is the cycle_shift value. For bits [4:3], clear to 0x0 for no offset, program to 0x1 for -1 cycle, program to 0x2 for +1 cycle, or program to 0x3 for -2 cycles.
{0x4000+4i} CTLPHY_WRAP__CTL_CFG__CTLCFG_DENALI_PHY_{i} (i=546..549)
  [20:16] PHY_ADR{i-544}_SW_WRADDR_SHIFT_0 — Manual override of CA bit {i-544} of automatic half_cycle_shift/cycle_shift for address slice 0. Bit [0] enables override of half_cycle_shift. Bit [1] is the half_cycle_shift value. Bit [2] enables override of cycle shift. Bits [4:3] is the cycle_shift value. For bits [4:3], clear to 0x0 for no offset, program to 0x1 for -1 cycle, program to 0x2 for +1 cycle, or program to 0x3 for -2 cycles.
  [10:0] PHY_ADR{i-545}_CLK_WR_SLAVE_DELAY_0 — CA bit {i-545} slave delay setting for address slice 0.
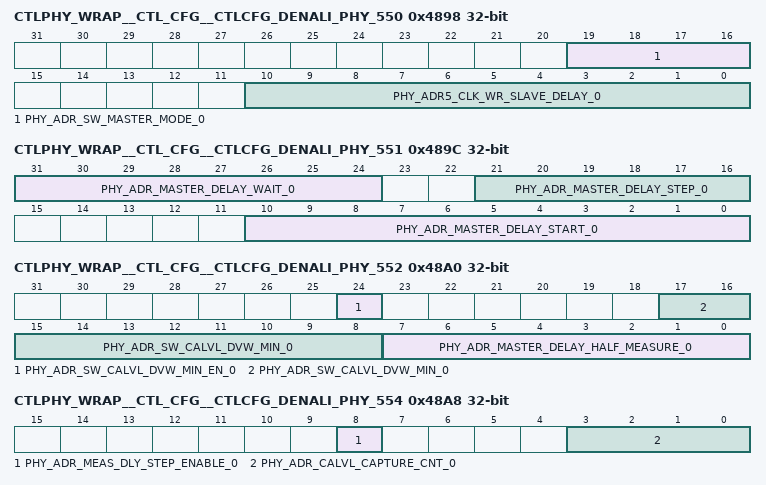
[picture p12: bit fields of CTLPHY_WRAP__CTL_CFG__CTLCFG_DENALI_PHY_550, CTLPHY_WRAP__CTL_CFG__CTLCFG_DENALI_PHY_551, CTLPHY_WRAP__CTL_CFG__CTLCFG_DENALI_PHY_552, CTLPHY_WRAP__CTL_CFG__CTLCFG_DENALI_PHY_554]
0x4898 CTLPHY_WRAP__CTL_CFG__CTLCFG_DENALI_PHY_550
  [19:16] PHY_ADR_SW_MASTER_MODE_0 — Master delay line override settings for address slice 0. Bit [0] enables software half clock mode. Bit [1] is the software half clock mode value. Bit [2] enables software bypass mode. Bit [3] is the software bypass mode value.
  [10:0] PHY_ADR5_CLK_WR_SLAVE_DELAY_0 — CA bit 5 slave delay setting for address slice 0.
0x489C CTLPHY_WRAP__CTL_CFG__CTLCFG_DENALI_PHY_551
  [31:24] PHY_ADR_MASTER_DELAY_WAIT_0 — Wait cycles for master delay line locking algorithm for address slice 0. Bits [3:0] is the cycle wait count after a calibration clock setting change. Bits [7:4] is the cycle wait count after a master delay setting change.
  [21:16] PHY_ADR_MASTER_DELAY_STEP_0 — Incremental step size for master delay line locking algorithm for address slice 0.
  [10:0] PHY_ADR_MASTER_DELAY_START_0 — Start value for master delay line locking algorithm for address slice 0.
0x48A0 CTLPHY_WRAP__CTL_CFG__CTLCFG_DENALI_PHY_552
  [24] PHY_ADR_SW_CALVL_DVW_MIN_EN_0 — Enables the software override data valid window size during CA training for address slice 0.
  [17:8] PHY_ADR_SW_CALVL_DVW_MIN_0 — Sets the software override data valid window size during CA training for address slice 0.
  [7:0] PHY_ADR_MASTER_DELAY_HALF_MEASURE_0 — Defines the number of delay line elements to be considered in determing whether to lock to a half clock cycle for the master in address slice 0
0x48A4 CTLPHY_WRAP__CTL_CFG__CTLCFG_DENALI_PHY_553
  [3:0] PHY_ADR_CALVL_DLY_STEP_0 — Sets the delay step size plus 1 during CA training for address slice 0.
0x48A8 CTLPHY_WRAP__CTL_CFG__CTLCFG_DENALI_PHY_554
  [8] PHY_ADR_MEAS_DLY_STEP_ENABLE_0 — Enables delay parameter setting using phy_adr_meas_dly_step_value for address slice 0.
  [3:0] PHY_ADR_CALVL_CAPTURE_CNT_0 — Number of samples to take at each ADDR slave delay setting during CA training for address slice 0.
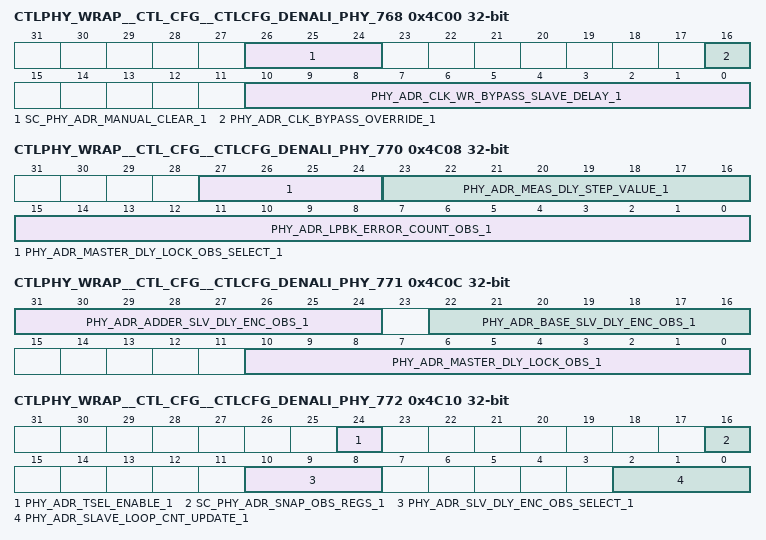
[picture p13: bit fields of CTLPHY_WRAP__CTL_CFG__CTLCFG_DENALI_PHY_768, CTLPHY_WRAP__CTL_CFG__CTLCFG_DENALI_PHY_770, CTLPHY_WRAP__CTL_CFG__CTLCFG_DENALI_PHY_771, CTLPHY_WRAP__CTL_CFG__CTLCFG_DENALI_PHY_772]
0x4C00 CTLPHY_WRAP__CTL_CFG__CTLCFG_DENALI_PHY_768 access per field
  [26:24] SC_PHY_ADR_MANUAL_CLEAR_1 wo — Manual reset/clear of internal logic for address slice 1. Bit [0] is reset of master delay min/max lock values. Bit [1] is manual reset of master delay unlock counter. Bit [2] clears the loopback error/results registers. Set each bit to 1 to reset. WRITE-ONLY
  [16] PHY_ADR_CLK_BYPASS_OVERRIDE_1 rw — Bypass mode override setting for address slice 1. Set to 1 to enable.
  [10:0] PHY_ADR_CLK_WR_BYPASS_SLAVE_DELAY_1 rw — Command/Address clock bypass mode slave delay setting for address slice 1.
0x4C04 CTLPHY_WRAP__CTL_CFG__CTLCFG_DENALI_PHY_769 ro reset 0x1000
  [31:0] PHY_ADR_LPBK_RESULT_OBS_1 — Observation register containing loopback status/results for address slice 1. READ-ONLY
0x4C08 CTLPHY_WRAP__CTL_CFG__CTLCFG_DENALI_PHY_770 access per field
  [27:24] PHY_ADR_MASTER_DLY_LOCK_OBS_SELECT_1 rw — Select value to map the internal master delay observation registers to the accessible master delay observation register for address slice 1.
  [23:16] PHY_ADR_MEAS_DLY_STEP_VALUE_1 ro — Contains the fraction of a cycle in 1 delay element numerator with demominator of 512, for address slice 1. READ-ONLY
  [15:0] PHY_ADR_LPBK_ERROR_COUNT_OBS_1 ro — Observation register containing total number of loopback error data for address slice 1. READ-ONLY
0x4C0C CTLPHY_WRAP__CTL_CFG__CTLCFG_DENALI_PHY_771 ro
  [31:24] PHY_ADR_ADDER_SLV_DLY_ENC_OBS_1 — Observation register containing addr slave delay for address slice 1. READ-ONLY
  [22:16] PHY_ADR_BASE_SLV_DLY_ENC_OBS_1 — Observation register containing base slave delay for address slice 1. READ-ONLY
  [10:0] PHY_ADR_MASTER_DLY_LOCK_OBS_1 — Observation register containing master delay results for address slice 1. READ-ONLY
0x4C10 CTLPHY_WRAP__CTL_CFG__CTLCFG_DENALI_PHY_772 access per field
  [24] PHY_ADR_TSEL_ENABLE_1 rw — Enables tsel_en for address slice 1.
  [16] SC_PHY_ADR_SNAP_OBS_REGS_1 wo — Initiates a snapshot of the internal observation registers for address slice 1. Set to 1 to trigger. WRITE-ONLY
  [10:8] PHY_ADR_SLV_DLY_ENC_OBS_SELECT_1 rw — Select value to map the addr bits delay observation registers to the accessible delay observation register for address slice 1.
  [2:0] PHY_ADR_SLAVE_LOOP_CNT_UPDATE_1 rw — Reserved for address slice 1.
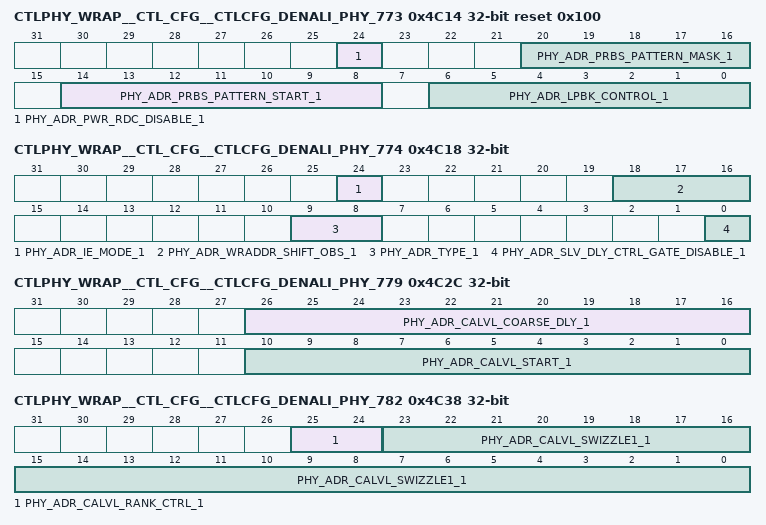
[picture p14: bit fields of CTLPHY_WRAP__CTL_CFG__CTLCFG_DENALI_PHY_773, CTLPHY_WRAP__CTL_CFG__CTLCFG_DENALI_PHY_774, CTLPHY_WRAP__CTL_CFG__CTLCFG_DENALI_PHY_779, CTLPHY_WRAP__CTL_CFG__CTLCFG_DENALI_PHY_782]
0x4C14 CTLPHY_WRAP__CTL_CFG__CTLCFG_DENALI_PHY_773 reset 0x100
  [24] PHY_ADR_PWR_RDC_DISABLE_1 — Power reduction disable for address slice 1.
  [20:16] PHY_ADR_PRBS_PATTERN_MASK_1 — PRBS7 mask signal for address slice 1.
  [14:8] PHY_ADR_PRBS_PATTERN_START_1 — PRBS7 start pattern for address slice 1.
  [6:0] PHY_ADR_LPBK_CONTROL_1 — Loopback control bits for address slice 1.
0x4C18 CTLPHY_WRAP__CTL_CFG__CTLCFG_DENALI_PHY_774 access per field
  [24] PHY_ADR_IE_MODE_1 rw — Input enable control for address slice 1.
  [18:16] PHY_ADR_WRADDR_SHIFT_OBS_1 ro — Observation register containing automatic half cycle and cycle shift values for address slice 1. READ-ONLY
  [9:8] PHY_ADR_TYPE_1 rw — DRAM type for address slice 1.
  [0] PHY_ADR_SLV_DLY_CTRL_GATE_DISABLE_1 rw — Power reduction slv_dly_control block gate disable for address slice 1.
0x4C1C CTLPHY_WRAP__CTL_CFG__CTLCFG_DENALI_PHY_775
  [26:0] PHY_ADR_DDL_MODE_1 — DDL mode for address slice 1.
0x4C20 CTLPHY_WRAP__CTL_CFG__CTLCFG_DENALI_PHY_776
  [5:0] PHY_ADR_DDL_MASK_1 — DDL mask for address slice 1.
0x4C24 CTLPHY_WRAP__CTL_CFG__CTLCFG_DENALI_PHY_777 ro
  [31:0] PHY_ADR_DDL_TEST_OBS_1 — Observation register containing DDL test bits for address slice 1. READ-ONLY
0x4C28 CTLPHY_WRAP__CTL_CFG__CTLCFG_DENALI_PHY_778 ro
  [31:0] PHY_ADR_DDL_TEST_MSTR_DLY_OBS_1 — Observation register containing master DDL bits for address slice 1. READ-ONLY
0x4C2C CTLPHY_WRAP__CTL_CFG__CTLCFG_DENALI_PHY_779
  [26:16] PHY_ADR_CALVL_COARSE_DLY_1 — Coarse CA training DDL increment value for address slice 1.
  [10:0] PHY_ADR_CALVL_START_1 — CA training DDL start value for address slice 1.
0x4C30 CTLPHY_WRAP__CTL_CFG__CTLCFG_DENALI_PHY_780
  [10:0] PHY_ADR_CALVL_QTR_1 — CA training DDL quarter cycle delay value for address slice 1.
0x4C34 CTLPHY_WRAP__CTL_CFG__CTLCFG_DENALI_PHY_781
  [23:0] PHY_ADR_CALVL_SWIZZLE0_1 — CA training RD DQ bit swizzle map 0 for address slice 1.
0x4C38 CTLPHY_WRAP__CTL_CFG__CTLCFG_DENALI_PHY_782
  [25:24] PHY_ADR_CALVL_RANK_CTRL_1 — CA training rank aggregation control bits for address slice 1.
  [23:0] PHY_ADR_CALVL_SWIZZLE1_1 — CA training RD DQ bit swizzle map 1 for address slice 1.
0x4C3C CTLPHY_WRAP__CTL_CFG__CTLCFG_DENALI_PHY_783
  [24:16] PHY_ADR_CALVL_PERIODIC_START_OFFSET_1 — Relative offset to start periodic CALVL from previous result
  [11:8] PHY_ADR_CALVL_RESP_WAIT_CNT_1 — Number of samples to wait before sampling response during CA training for address slice 1.
  [1:0] PHY_ADR_CALVL_NUM_PATTERNS_1 — Number of patterns to use during CA training for address slice 1.
0x4C40 CTLPHY_WRAP__CTL_CFG__CTLCFG_DENALI_PHY_784 access per field
  [26:24] PHY_ADR_CALVL_OBS_SELECT_1 rw — CA bit lane to observe result from OBS0 during CA training for address slice 1.
  [16] SC_PHY_ADR_CALVL_ERROR_CLR_1 wo — Clears the CA training state machine error status for address slice 1. Set to 1 to trigger. WRITE-ONLY
  [8] SC_PHY_ADR_CALVL_DEBUG_CONT_1 wo — Allows the CA training state machine to advance [when in debug mode] for address slice 1. Set to 1 to trigger. WRITE-ONLY
  [0] PHY_ADR_CALVL_DEBUG_MODE_1 rw — Enables CA training debug mode for address slice 1. Set to 1 to enable.
0x4C44 CTLPHY_WRAP__CTL_CFG__CTLCFG_DENALI_PHY_785 ro
  [31:0] PHY_ADR_CALVL_OBS0_1 — Observation register contains lane specific CA training bits for slice 1. READ-ONLY
0x4C48 CTLPHY_WRAP__CTL_CFG__CTLCFG_DENALI_PHY_786 ro
  [31:0] PHY_ADR_CALVL_OBS1_1 — Observation register contains general CA training bits for slice 1. READ-ONLY
0x4C4C CTLPHY_WRAP__CTL_CFG__CTLCFG_DENALI_PHY_787 ro reset 0x100
  [31:0] PHY_ADR_CALVL_OBS2_1 — Observation register contains periodic CA training bits for slice 1. READ-ONLY
0x4C50 CTLPHY_WRAP__CTL_CFG__CTLCFG_DENALI_PHY_788
  [19:0] PHY_ADR_CALVL_FG_0_1 — CA training foreground pattern 0 for address slice 1.
0x4C54 CTLPHY_WRAP__CTL_CFG__CTLCFG_DENALI_PHY_789
  [19:0] PHY_ADR_CALVL_BG_0_1 — CA training background pattern 0 for address slice 1.
0x4C58 CTLPHY_WRAP__CTL_CFG__CTLCFG_DENALI_PHY_790
  [19:0] PHY_ADR_CALVL_FG_1_1 — CA training foreground pattern 1 for address slice 1.
0x4C5C CTLPHY_WRAP__CTL_CFG__CTLCFG_DENALI_PHY_791
  [19:0] PHY_ADR_CALVL_BG_1_1 — CA training background pattern 1 for address slice 1.
0x4C60 CTLPHY_WRAP__CTL_CFG__CTLCFG_DENALI_PHY_792
  [19:0] PHY_ADR_CALVL_FG_2_1 — CA training foreground pattern 2 for address slice 1.
0x4C64 CTLPHY_WRAP__CTL_CFG__CTLCFG_DENALI_PHY_793
  [19:0] PHY_ADR_CALVL_BG_2_1 — CA training background pattern 2 for address slice 1.
0x4C68 CTLPHY_WRAP__CTL_CFG__CTLCFG_DENALI_PHY_794
  [19:0] PHY_ADR_CALVL_FG_3_1 — CA training foreground pattern 3 for address slice 1.
0x4C6C CTLPHY_WRAP__CTL_CFG__CTLCFG_DENALI_PHY_795
  [19:0] PHY_ADR_CALVL_BG_3_1 — CA training background pattern 3 for address slice 1.
0x4C70 CTLPHY_WRAP__CTL_CFG__CTLCFG_DENALI_PHY_796
  [29:0] PHY_ADR_ADDR_SEL_1 — Selects which DFI address pins connect to which CA pins for LPDDR3/4 for address slice 1.
0x4C74 CTLPHY_WRAP__CTL_CFG__CTLCFG_DENALI_PHY_797
  [29:24] PHY_ADR_SEG_MASK_1 — Segment mask bit for address slice 1. Set to 1 to indicate that the bit is either CA 4 or CA 9.
  [21:16] PHY_ADR_BIT_MASK_1 — Mask bit for address slice 1. Set to 1 to indicate that the bit is used.
  [9:0] PHY_ADR_LP4_BOOT_SLV_DELAY_1 — Address slave delay setting during the LPDDR4 boot frequency operation for address slice 1.
0x4C78 CTLPHY_WRAP__CTL_CFG__CTLCFG_DENALI_PHY_798
  [29:24] PHY_ADR_SW_TXIO_CTRL_1 — Controls address pad output enable for address slice 1. Set to 1 to disable output enable.
  [19:16] PHY_ADR_STATIC_TOG_DISABLE_1 — Toggle control during static activity for address slice 1. Set bit to dsiable toggling, bit0: Write path delay line, bit1: Read path delay line, bit2: Read data path, bit3: clk_phy, bit4: master delay line.
  [13:8] PHY_ADR_CSLVL_TRAIN_MASK_1 — Mask bit for CS training participation for address slice 1. Set to 1 to indicate that the bit is participating in CS training.
  [5:0] PHY_ADR_CALVL_TRAIN_MASK_1 — Mask bit for CA training participation for address slice 1. Set to 1 to indicate that the bit is participating in CA training.
0x4C7C CTLPHY_WRAP__CTL_CFG__CTLCFG_DENALI_PHY_799
  [5:0] PHY_ADR_SW_TXPWR_CTRL_1 — Disable address output enables in deep sleep mode for address slice 1.
0x4C80 CTLPHY_WRAP__CTL_CFG__CTLCFG_DENALI_PHY_800
  [26:24] PHY_PAD_ADR_RX_PCLK_CLK_SEL_1 — Reserved for address slice 1.
  [18:8] PHY_PAD_ADR_IO_CFG_1 — Controls I/O pads for address pad for address slice 1. Bits [10:5] = Park value, bits [4] park override, bits [2:0] clk divider.
  [7:0] PHY_ADR_TSEL_SELECT_1 — Tsel select values for address slice 1.
0x4C84 CTLPHY_WRAP__CTL_CFG__CTLCFG_DENALI_PHY_801
  [28:24] PHY_ADR1_SW_WRADDR_SHIFT_1 — Manual override of CA bit 1 of automatic half_cycle_shift/cycle_shift for address slice 1. Bit [0] enables override of half_cycle_shift. Bit [1] is the half_cycle_shift value. Bit [2] enables override of cycle shift. Bits [4:3] is the cycle_shift value. For bits [4:3], clear to 0x0 for no offset, program to 0x1 for -1 cycle, program to 0x2 for +1 cycle, or program to 0x3 for -2 cycles.
  [18:8] PHY_ADR0_CLK_WR_SLAVE_DELAY_1 — CA bit 0 slave delay setting for address slice 1.
  [4:0] PHY_ADR0_SW_WRADDR_SHIFT_1 — Manual override of CA bit 0 of automatic half_cycle_shift/cycle_shift for address slice 1. Bit [0] enables override of half_cycle_shift. Bit [1] is the half_cycle_shift value. Bit [2] enables override of cycle shift. Bits [4:3] is the cycle_shift value. For bits [4:3], clear to 0x0 for no offset, program to 0x1 for -1 cycle, program to 0x2 for +1 cycle, or program to 0x3 for -2 cycles.
{0x4000+4i} CTLPHY_WRAP__CTL_CFG__CTLCFG_DENALI_PHY_{i} (i=802..805)
  [20:16] PHY_ADR{i-800}_SW_WRADDR_SHIFT_1 — Manual override of CA bit {i-800} of automatic half_cycle_shift/cycle_shift for address slice 1. Bit [0] enables override of half_cycle_shift. Bit [1] is the half_cycle_shift value. Bit [2] enables override of cycle shift. Bits [4:3] is the cycle_shift value. For bits [4:3], clear to 0x0 for no offset, program to 0x1 for -1 cycle, program to 0x2 for +1 cycle, or program to 0x3 for -2 cycles.
  [10:0] PHY_ADR{i-801}_CLK_WR_SLAVE_DELAY_1 — CA bit {i-801} slave delay setting for address slice 1.
0x4C98 CTLPHY_WRAP__CTL_CFG__CTLCFG_DENALI_PHY_806
  [19:16] PHY_ADR_SW_MASTER_MODE_1 — Master delay line override settings for address slice 1. Bit [0] enables software half clock mode. Bit [1] is the software half clock mode value. Bit [2] enables software bypass mode. Bit [3] is the software bypass mode value.
  [10:0] PHY_ADR5_CLK_WR_SLAVE_DELAY_1 — CA bit 5 slave delay setting for address slice 1.
0x4C9C CTLPHY_WRAP__CTL_CFG__CTLCFG_DENALI_PHY_807
  [31:24] PHY_ADR_MASTER_DELAY_WAIT_1 — Wait cycles for master delay line locking algorithm for address slice 1. Bits [3:0] is the cycle wait count after a calibration clock setting change. Bits [7:4] is the cycle wait count after a master delay setting change.
  [21:16] PHY_ADR_MASTER_DELAY_STEP_1 — Incremental step size for master delay line locking algorithm for address slice 1.
  [10:0] PHY_ADR_MASTER_DELAY_START_1 — Start value for master delay line locking algorithm for address slice 1.
0x4CA0 CTLPHY_WRAP__CTL_CFG__CTLCFG_DENALI_PHY_808
  [24] PHY_ADR_SW_CALVL_DVW_MIN_EN_1 — Enables the software override data valid window size during CA training for address slice 1.
  [17:8] PHY_ADR_SW_CALVL_DVW_MIN_1 — Sets the software override data valid window size during CA training for address slice 1.
  [7:0] PHY_ADR_MASTER_DELAY_HALF_MEASURE_1 — Defines the number of delay line elements to be considered in determing whether to lock to a half clock cycle for the master in address slice 1
0x4CA4 CTLPHY_WRAP__CTL_CFG__CTLCFG_DENALI_PHY_809
  [3:0] PHY_ADR_CALVL_DLY_STEP_1 — Sets the delay step size plus 1 during CA training for address slice 1.
0x4CA8 CTLPHY_WRAP__CTL_CFG__CTLCFG_DENALI_PHY_810
  [8] PHY_ADR_MEAS_DLY_STEP_ENABLE_1 — Enables delay parameter setting using phy_adr_meas_dly_step_value for address slice 1.
  [3:0] PHY_ADR_CALVL_CAPTURE_CNT_1 — Number of samples to take at each ADDR slave delay setting during CA training for address slice 1.
0x5000 CTLPHY_WRAP__CTL_CFG__CTLCFG_DENALI_PHY_1024 access per field
  [26:24] SC_PHY_ADR_MANUAL_CLEAR_2 wo — Manual reset/clear of internal logic for address slice 2. Bit [0] is reset of master delay min/max lock values. Bit [1] is manual reset of master delay unlock counter. Bit [2] clears the loopback error/results registers. Set each bit to 1 to reset. WRITE-ONLY
  [16] PHY_ADR_CLK_BYPASS_OVERRIDE_2 rw — Bypass mode override setting for address slice 2. Set to 1 to enable.
  [10:0] PHY_ADR_CLK_WR_BYPASS_SLAVE_DELAY_2 rw — Command/Address clock bypass mode slave delay setting for address slice 2.
0x5004 CTLPHY_WRAP__CTL_CFG__CTLCFG_DENALI_PHY_1025 ro reset 0x1000
  [31:0] PHY_ADR_LPBK_RESULT_OBS_2 — Observation register containing loopback status/results for address slice 2. READ-ONLY
0x5008 CTLPHY_WRAP__CTL_CFG__CTLCFG_DENALI_PHY_1026 access per field
  [27:24] PHY_ADR_MASTER_DLY_LOCK_OBS_SELECT_2 rw — Select value to map the internal master delay observation registers to the accessible master delay observation register for address slice 2.
  [23:16] PHY_ADR_MEAS_DLY_STEP_VALUE_2 ro — Contains the fraction of a cycle in 1 delay element numerator with demominator of 512, for address slice 2. READ-ONLY
  [15:0] PHY_ADR_LPBK_ERROR_COUNT_OBS_2 ro — Observation register containing total number of loopback error data for address slice 2. READ-ONLY
0x500C CTLPHY_WRAP__CTL_CFG__CTLCFG_DENALI_PHY_1027 ro
  [31:24] PHY_ADR_ADDER_SLV_DLY_ENC_OBS_2 — Observation register containing addr slave delay for address slice 2. READ-ONLY
  [22:16] PHY_ADR_BASE_SLV_DLY_ENC_OBS_2 — Observation register containing base slave delay for address slice 2. READ-ONLY
  [10:0] PHY_ADR_MASTER_DLY_LOCK_OBS_2 — Observation register containing master delay results for address slice 2. READ-ONLY
0x5010 CTLPHY_WRAP__CTL_CFG__CTLCFG_DENALI_PHY_1028 access per field
  [24] PHY_ADR_TSEL_ENABLE_2 rw — Enables tsel_en for address slice 2.
  [16] SC_PHY_ADR_SNAP_OBS_REGS_2 wo — Initiates a snapshot of the internal observation registers for address slice 2. Set to 1 to trigger. WRITE-ONLY
  [10:8] PHY_ADR_SLV_DLY_ENC_OBS_SELECT_2 rw — Select value to map the addr bits delay observation registers to the accessible delay observation register for address slice 2.
  [2:0] PHY_ADR_SLAVE_LOOP_CNT_UPDATE_2 rw — Reserved for address slice 2.
